# ESP32-S2 register map
Vendor: ESPRESSIF SYSTEMS (SHANGHAI) CO., LTD.; Series: ESP32 S-Series; File version: 20
CPU: Xtensa LX7 r0p0, little endian, no MPU, no FPU, 0 interrupt priority bits
Address unit: 32 bits
Registers are 32-bit, read-write, reset 0x0 unless marked. A register's access mark holds for its fields unless they carry their own. Offsets are from the block's base; [hi:lo] are bit positions; {n}, {i} and the like mark numbered series.

## RMT — Remote Control
Base 0x3F416000
{0x0+4i} CH{i}DATA (i=0..3) ro — The read and write data register for CHANNEL{i} by apb fifo access.
  [31:0] CH_DATA
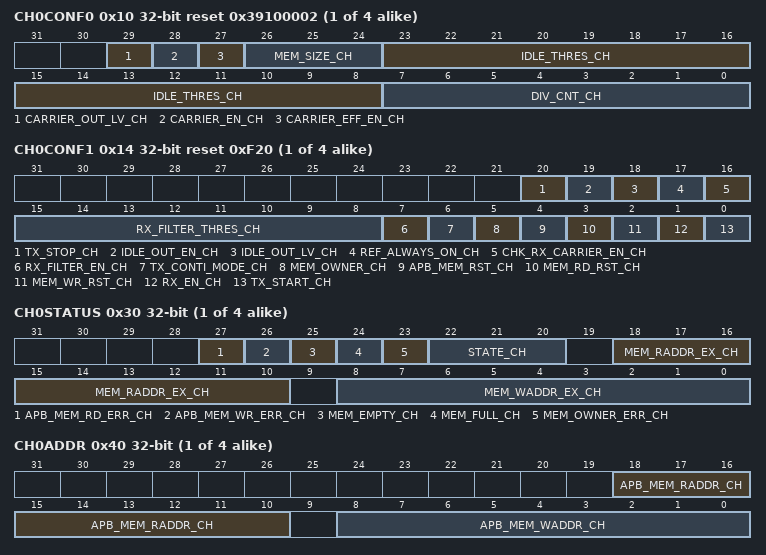
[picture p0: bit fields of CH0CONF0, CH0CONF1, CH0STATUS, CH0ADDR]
{0x10+8i} CH{i}CONF0 (i=0..3) reset 0x39100002 — Channel {i} configure register 0
  [29] CARRIER_OUT_LV_CH — This bit is used to configure the position of carrier wave for CHANNEL%s. 1'h0: add carrier wave on low level. 1'h1: add carrier wave on high level.
  [28] CARRIER_EN_CH — This is the carrier modulation enable-control bit for CHANNEL%s. 1: Add carrier modulation in the output signal. 0: No carrier modulation in sig_out.
  [27] CARRIER_EFF_EN_CH — 1: Add carrier modulation on the output signal only at the send data state for CHANNEL%s. 0: Add carrier modulation on the output signal at all state for CHANNEL%s. Only valid when RMT_CARRIER_EN_CH%s is 1.
  [26:24] MEM_SIZE_CH — This register is used to configure the maximum size of memory allocated to CHANNEL%s.
  [23:8] IDLE_THRES_CH — When no edge is detected on the input signal and continuous clock cycles is longer than this register value, received process is finished.
  [7:0] DIV_CNT_CH — This register is used to configure the divider for clock of CHANNEL%s.
{0x14+8i} CH{i}CONF1 (i=0..3) access per field reset 0xF20 — Channel {i} configure register 1
  [20] TX_STOP_CH rw — Set this bit to stop the transmitter of CHANNEL%s sending data out.
  [19] IDLE_OUT_EN_CH rw — This is the output enable-control bit for CHANNEL%s in IDLE state.
  [18] IDLE_OUT_LV_CH rw — This bit configures the level of output signal in CHANNEL%s when the latter is in IDLE state.
  [17] REF_ALWAYS_ON_CH rw — This bit is used to select the base clock for CHANNEL%s. 1'h1: clk_apb 1'h0:clk_ref
  [16] CHK_RX_CARRIER_EN_CH rw — Set this bit to enable memory loop read mode when carrier modulation is enabled for channel %s.
  [15:8] RX_FILTER_THRES_CH rw — Ignores the input pulse when its width is smaller than this register value in APB clock periods (in receive mode).
  [7] RX_FILTER_EN_CH rw — This is the receive filter's enable bit for CHANNEL%s.
  [6] TX_CONTI_MODE_CH rw — Set this bit to restart transmission from the first data to the last data in CHANNEL%s.
  [5] MEM_OWNER_CH rw — This register marks the ownership of CHANNEL%s's ram block. 1'h1: Receiver is using the ram. 1'h0: Transmitter is using the ram.
  [4] APB_MEM_RST_CH wo — Set this bit to reset W/R ram address for CHANNEL%s by accessing apb fifo.
  [3] MEM_RD_RST_CH wo — Set this bit to reset read ram address for CHANNEL%s by accessing transmitter.
  [2] MEM_WR_RST_CH wo — Set this bit to reset write ram address for CHANNEL%s by accessing receiver.
  [1] RX_EN_CH rw — Set this bit to enable receiver to receive data on CHANNEL%s.
  [0] TX_START_CH rw — Set this bit to start sending data on CHANNEL%s.
{0x30+4i} CH{i}STATUS (i=0..3) ro — Channel {i} status register
  [27] APB_MEM_RD_ERR_CH — This status bit will be set if the offset address out of memory size when reads via APB bus.
  [26] APB_MEM_WR_ERR_CH — This status bit will be set if the offset address out of memory size when writes via APB bus.
  [25] MEM_EMPTY_CH — This status bit will be set when the data to be set is more than memory size and the wraparound mode is disabled.
  [24] MEM_FULL_CH — This status bit will be set if the receiver receives more data than the memory size.
  [23] MEM_OWNER_ERR_CH — This status bit will be set when the ownership of memory block is wrong.
  [22:20] STATE_CH — This register records the FSM status of CHANNEL%s.
  [18:10] MEM_RADDR_EX_CH — This register records the memory address offset when transmitter of CHANNEL%s is using the RAM.
  [8:0] MEM_WADDR_EX_CH — This register records the memory address offset when receiver of CHANNEL%s is using the RAM.
{0x40+4i} CH{i}ADDR (i=0..3) ro — Channel {i} address register
  [18:10] APB_MEM_RADDR_CH — This register records the memory address offset when reads RAM over APB bus.
  [8:0] APB_MEM_WADDR_CH — This register records the memory address offset when writes RAM over APB bus.
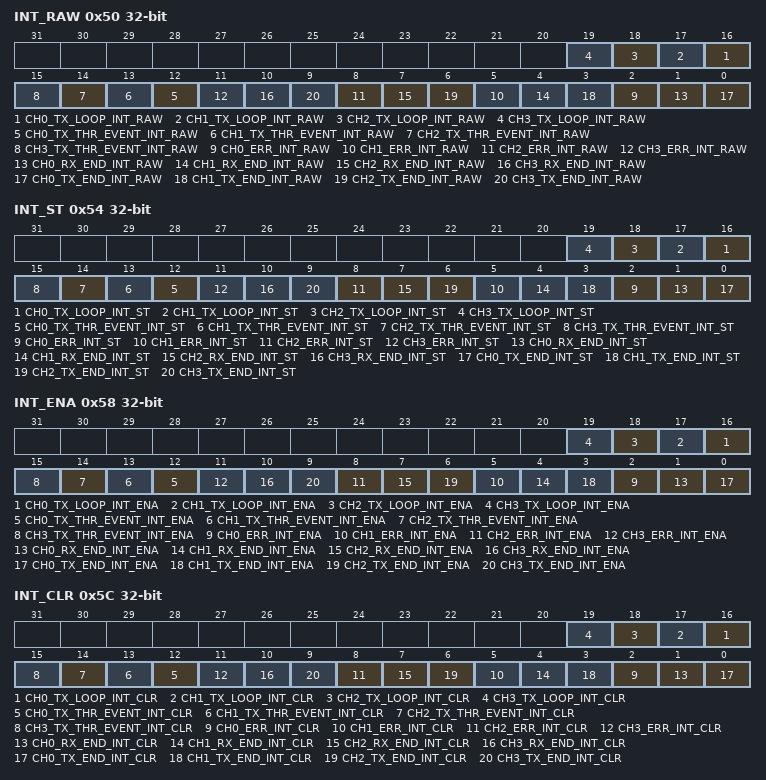
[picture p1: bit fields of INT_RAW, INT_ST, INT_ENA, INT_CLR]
0x50 INT_RAW ro — Raw interrupt status
  [n+16] CH{n}_TX_LOOP_INT_RAW (n=0..3) — The interrupt raw bit for CHANNEL{n}. Triggered when the loop count reaches the configured threshold value.
  [n+12] CH{n}_TX_THR_EVENT_INT_RAW (n=0..3) — The interrupt raw bit for CHANNEL{n}. Triggered when transmitter sent more data than configured value.
  [3n+2] CH{n}_ERR_INT_RAW (n=0..3) — The interrupt raw bit for CHANNEL{n}. Triggered when error occurs.
  [3n+1] CH{n}_RX_END_INT_RAW (n=0..3) — The interrupt raw bit for CHANNEL{n}. Triggered when reception done.
  [3n] CH{n}_TX_END_INT_RAW (n=0..3) — The interrupt raw bit for CHANNEL{n}. Triggered when transmission done.
0x54 INT_ST ro — Masked interrupt status
  [n+16] CH{n}_TX_LOOP_INT_ST (n=0..3) — The masked interrupt status bit for CH{n}_TX_LOOP_INT.
  [n+12] CH{n}_TX_THR_EVENT_INT_ST (n=0..3) — The masked interrupt status bit for CH{n}_TX_THR_EVENT_INT.
  [3n+2] CH{n}_ERR_INT_ST (n=0..3) — The masked interrupt status bit for CH{n}_ERR_INT.
  [3n+1] CH{n}_RX_END_INT_ST (n=0..3) — The masked interrupt status bit for CH{n}_RX_END_INT.
  [3n] CH{n}_TX_END_INT_ST (n=0..3) — The masked interrupt status bit for CH{n}_TX_END_INT.
0x58 INT_ENA — Interrupt enable bits
  [n+16] CH{n}_TX_LOOP_INT_ENA (n=0..3) — The interrupt enabled bit for CH{n}_TX_LOOP_INT.
  [n+12] CH{n}_TX_THR_EVENT_INT_ENA (n=0..3) — The interrupt enabled bit for CH{n}_TX_THR_EVENT_INT.
  [3n+2] CH{n}_ERR_INT_ENA (n=0..3) — The interrupt enabled bit for CH{n}_ERR_INT.
  [3n+1] CH{n}_RX_END_INT_ENA (n=0..3) — The interrupt enabled bit for CH{n}_RX_END_INT.
  [3n] CH{n}_TX_END_INT_ENA (n=0..3) — The interrupt enabled bit for CH{n}_TX_END_INT.
0x5C INT_CLR wo — Interrupt clear bits
  [n+16] CH{n}_TX_LOOP_INT_CLR (n=0..3) — Set this bit to clear the CH{n}_TX_LOOP_INT interrupt.
  [n+12] CH{n}_TX_THR_EVENT_INT_CLR (n=0..3) — Set this bit to clear the CH{n}_TX_THR_EVENT_INT interrupt.
  [3n+2] CH{n}_ERR_INT_CLR (n=0..3) — Set this bit to clear the CH{n}_ERR_INT interrupt.
  [3n+1] CH{n}_RX_END_INT_CLR (n=0..3) — Set this bit to clear the CH{n}_RX_END_INT interrupt.
  [3n] CH{n}_TX_END_INT_CLR (n=0..3) — Set this bit to clear the CH{n}_TX_END_INT interrupt.
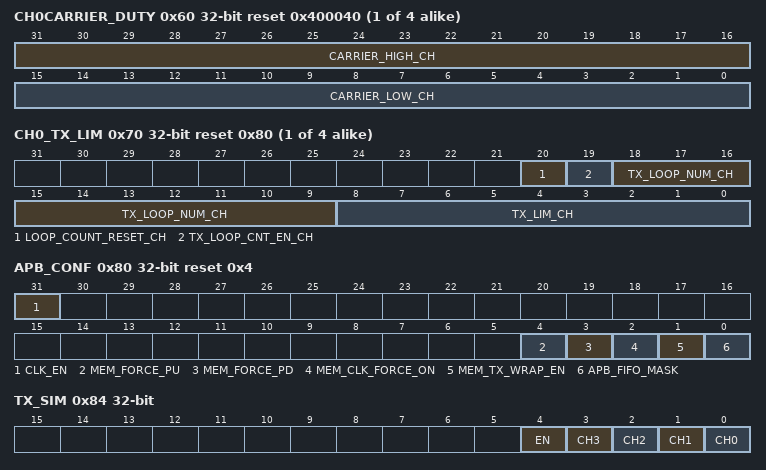
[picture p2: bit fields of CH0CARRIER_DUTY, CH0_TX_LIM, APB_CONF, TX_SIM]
{0x60+4i} CH{i}CARRIER_DUTY (i=0..3) reset 0x400040 — Channel {i} duty cycle configuration register
  [31:16] CARRIER_HIGH_CH — This register is used to configure carrier wave 's high level clock period for CHANNEL%s.
  [15:0] CARRIER_LOW_CH — This register is used to configure carrier wave 's low level clock period for CHANNEL%s.
{0x70+4i} CH{i}_TX_LIM (i=0..3) access per field reset 0x80 — Channel {i} Tx event configuration register
  [20] LOOP_COUNT_RESET_CH wo — This register is used to reset the loop count when tx_conti_mode is valid.
  [19] TX_LOOP_CNT_EN_CH rw — This register is the enabled bit for loop count.
  [18:9] TX_LOOP_NUM_CH rw — This register is used to configure the maximum loop count when tx_conti_mode is valid.
  [8:0] TX_LIM_CH rw — This register is used to configure the maximum entries that CHANNEL%s can send out.
0x80 APB_CONF reset 0x4 — RMT apb configuration register
  [31] CLK_EN — RMT register clock gate enable signal. 1: Power up the drive clock of registers. 0: Power down the drive clock of registers
  [4] MEM_FORCE_PU — 1: Disable RMT memory light sleep power down function. 0: Power down RMT memory when RMT is in light sleep mode.
  [3] MEM_FORCE_PD — Set this bit to power down RMT memory.
  [2] MEM_CLK_FORCE_ON — Set this bit to enable the clock for RMT memory.
  [1] MEM_TX_WRAP_EN — This is the enable bit for wraparound mode: it will resume sending at the start when the data to be sent is more than its memory size.
  [0] APB_FIFO_MASK — 1'h1: access memory directly. 1'h0: access memory by FIFO.
0x84 TX_SIM — RMT TX synchronous register
  [4] EN — This register is used to enable multiple of channels to start sending data synchronously.
  [n] CH{n} (n=0..3) — Set this bit to enable CHANNEL{n} to start sending data synchronously with other enabled channels.
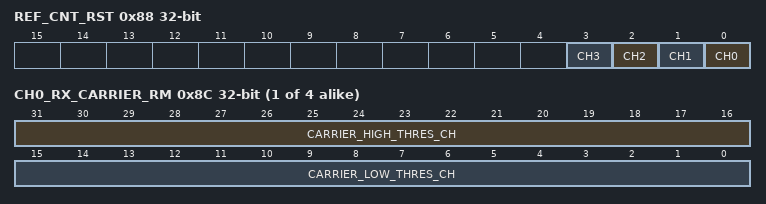
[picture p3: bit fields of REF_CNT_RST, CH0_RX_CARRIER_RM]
0x88 REF_CNT_RST — RMT clock divider reset register
  [n] CH{n} (n=0..3) — This register is used to reset the clock divider of CHANNEL{n}.
{0x8C+4i} CH{i}_RX_CARRIER_RM (i=0..3) — Channel {i} carrier remove register
  [31:16] CARRIER_HIGH_THRES_CH — The high level period in a carrier modulation mode is (REG_RMT_REG_CARRIER_HIGH_THRES_CH%s + 1) for channel %s.
  [15:0] CARRIER_LOW_THRES_CH — The low level period in a carrier modulation mode is (REG_RMT_REG_CARRIER_LOW_THRES_CH%s + 1) for channel %s.
0xFC DATE reset 0x19072601 — RMT version register
  [31:0] DATE — This is the version register.
